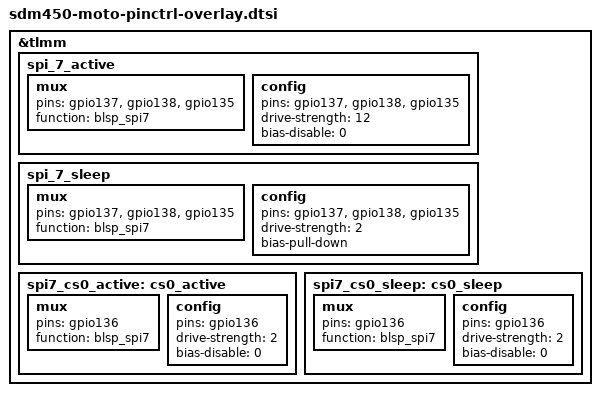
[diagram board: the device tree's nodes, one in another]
/*
 * Copyright (c) 2017-2018, The Linux Foundation. All rights reserved.
 *
 * This program is free software; you can redistribute it and/or modify
 * it under the terms of the GNU General Public License version 2 and
 * only version 2 as published by the Free Software Foundation.
 *
 * This program is distributed in the hope that it will be useful,
 * but WITHOUT ANY WARRANTY; without even the implied warranty of
 * MERCHANTABILITY or FITNESS FOR A PARTICULAR PURPOSE.  See the
 * GNU General Public License for more details.
 */
&tlmm{
	spi_7_active: spi_7_active {
		mux {
			/* MOSI, MISO, CLK */
			pins = "gpio137", "gpio138", "gpio135";
			function = "blsp_spi7";
		};

		config {
			pins = "gpio137", "gpio138", "gpio135";
			drive-strength = <12>; /* 12 MA */
			bias-disable = <0>; /* No PULL */
		};
	};

	spi_7_sleep: spi_7_sleep {
		mux {
			/* MOSI, MISO, CLK */
			pins = "gpio137", "gpio138", "gpio135";
			function = "blsp_spi7";
		};

		config {
			pins = "gpio137", "gpio138", "gpio135";
			drive-strength = <2>; /* 2 MA */
			bias-pull-down; /* PULL Down */
		};
	};

	spi7_cs0_active: cs0_active {
		mux {
			pins = "gpio136";
			function = "blsp_spi7";
		};

		config {
			pins = "gpio136";
			drive-strength = <2>;
			bias-disable = <0>;
		};
	};

	spi7_cs0_sleep: cs0_sleep {
		mux {
			pins = "gpio136";
			function = "blsp_spi7";
		};

		config {
			pins = "gpio136";
			drive-strength = <2>;
			bias-disable = <0>;
		};
	};
};

